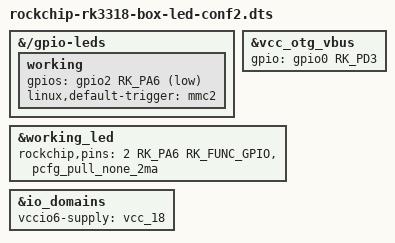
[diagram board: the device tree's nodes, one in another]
/dts-v1/;
/plugin/;

#include <dt-bindings/gpio/gpio.h>
#include <dt-bindings/input/input.h>
#include <dt-bindings/pinctrl/rockchip.h>

/ {

	fragment@0 {
		target-path = "/gpio-leds";
		__overlay__ {

			working {
				gpios = <&gpio2 RK_PA6 GPIO_ACTIVE_LOW>;
				linux,default-trigger = "mmc2";
			};

			/*
			 * no auxiliary led on X88_PRO_B boards
			 *
			auxiliary {
				gpios = <&gpio0 RK_PA1 GPIO_ACTIVE_HIGH>;
				label = "auxiliary";
				linux,default-trigger = "mmc2";
				default-state = "off";
				pinctrl-names = "default";
				pinctrl-0 = <&gpio_led_aux>;
			};
			*/

		};
	};

	fragment@1 {
		target = <&vcc_otg_vbus>;
		__overlay__ {

			gpio = <&gpio0 RK_PD3 GPIO_ACTIVE_HIGH>;

		};

	};

	fragment@2 {
		target = <&working_led>;
		__overlay__ {
			rockchip,pins = <2 RK_PA6 RK_FUNC_GPIO &pcfg_pull_none_2ma>;
		};
	};

	fragment@3 {
		target = <&io_domains>;
		__overlay__ {
			vccio6-supply = <&vcc_18>;
		};
	};

};
